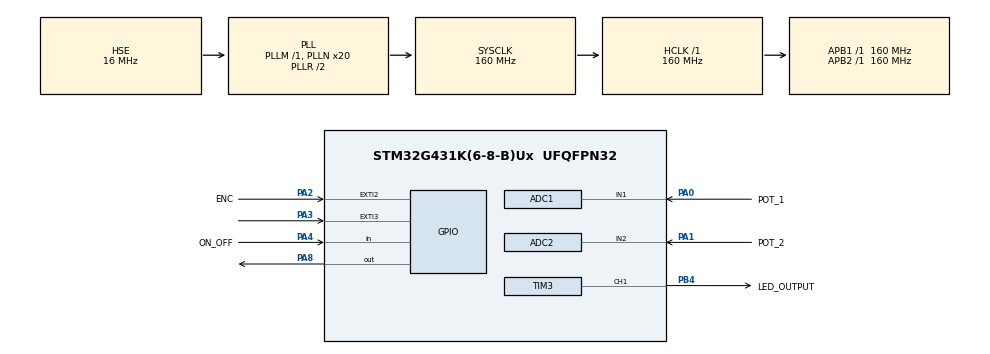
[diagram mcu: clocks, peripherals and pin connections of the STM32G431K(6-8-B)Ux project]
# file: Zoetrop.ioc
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ADC1.Channel-0\#ChannelRegularConversion=ADC_CHANNEL_1
ADC1.ContinuousConvMode=ENABLE
ADC1.NbrOfConversionFlag=1
ADC1.OffsetNumber-0\#ChannelRegularConversion=ADC_OFFSET_NONE
ADC1.Rank-0\#ChannelRegularConversion=1
ADC1.SamplingTime-0\#ChannelRegularConversion=ADC_SAMPLETIME_640CYCLES_5
ADC1.master=1
ADC2.Channel-0\#ChannelRegularConversion=ADC_CHANNEL_2
ADC2.ContinuousConvMode=ENABLE
ADC2.NbrOfConversionFlag=1
ADC2.OffsetNumber-0\#ChannelRegularConversion=ADC_OFFSET_NONE
ADC2.Rank-0\#ChannelRegularConversion=1
ADC2.SamplingTime-0\#ChannelRegularConversion=ADC_SAMPLETIME_640CYCLES_5
Mcu.Family=STM32G4
Mcu.Name=STM32G431K(6-8-B)Ux
Mcu.Package=UFQFPN32
NVIC.EXTI2_IRQn=true\:0\:0\:false\:false\:true\:true\:false
NVIC.EXTI3_IRQn=true\:0\:0\:false\:false\:true\:true\:false
NVIC.PriorityGroup=NVIC_PRIORITYGROUP_4
PA0.GPIO_Label=POT_1
PA0.Mode=IN1-Single-Ended
PA0.Signal=ADC1_IN1
PA1.GPIO_Label=POT_2
PA1.Mode=IN2-Single-Ended
PA1.Signal=ADC2_IN2
PA13.Mode=Trace_Asynchronous_SW
PA13.Signal=SYS_JTMS-SWDIO
PA14.Mode=Trace_Asynchronous_SW
PA14.Signal=SYS_JTCK-SWCLK
PA2.GPIO_Label=ENC
PA2.GPIO_ModeDefaultEXTI=GPIO_MODE_IT_RISING_FALLING
PA2.Signal=GPXTI2
PA3.Signal=GPXTI3
PA4.GPIO_Label=ON_OFF
PA4.Signal=GPIO_Input
PA8.PinState=GPIO_PIN_SET
PA8.Signal=GPIO_Output
PB3.Mode=Trace_Asynchronous_SW
PB3.Signal=SYS_JTDO-SWO
PB4.GPIO_Label=LED_OUTPUT
PB4.Signal=S_TIM3_CH1
PF0-OSC_IN.Mode=HSE-External-Oscillator
PF0-OSC_IN.Signal=RCC_OSC_IN
PF1-OSC_OUT.Mode=HSE-External-Oscillator
PF1-OSC_OUT.Signal=RCC_OSC_OUT
ProjectManager.HeapSize=0x200
ProjectManager.StackSize=0x400
ProjectManager.TargetToolchain=STM32CubeIDE
RCC.ADC12Freq_Value=160000000
RCC.AHBFreq_Value=160000000
RCC.APB1Freq_Value=160000000
RCC.APB1TimFreq_Value=160000000
RCC.APB2Freq_Value=160000000
RCC.APB2TimFreq_Value=160000000
RCC.CortexFreq_Value=160000000
RCC.EXTERNAL_CLOCK_VALUE=12288000
RCC.HCLKFreq_Value=160000000
RCC.HSE_VALUE=16000000
RCC.HSI48_VALUE=48000000
RCC.HSI_VALUE=16000000
RCC.LSE_VALUE=32768
RCC.PLLN=20
RCC.PLLSourceVirtual=RCC_PLLSOURCE_HSE
RCC.SYSCLKFreq_VALUE=160000000
RCC.SYSCLKSource=RCC_SYSCLKSOURCE_PLLCLK
RCC.USBFreq_Value=160000000
RCC.VCOOutputFreq_Value=320000000
SH.S_TIM3_CH1.0=TIM3_CH1,PWM Generation1 CH1
TIM1.PeriodNoDither=8000
TIM2.PeriodNoDither=100000000
TIM2.Prescaler=1599
TIM3.Channel-PWM\ Generation1\ CH1=TIM_CHANNEL_1
TIM3.ClockDivision=TIM_CLOCKDIVISION_DIV4
TIM3.OCMode_PWM-PWM\ Generation1\ CH1=TIM_OCMODE_PWM1
TIM3.Prescaler=1599
VP_SYS_VS_DBSignals.Mode=DisableDeadBatterySignals
VP_TIM1_VS_ClockSourceINT.Mode=Internal
VP_TIM2_VS_ClockSourceINT.Mode=Internal
VP_TIM3_VS_ClockSourceINT.Mode=Internal
board=custom

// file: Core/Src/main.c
/* USER CODE BEGIN Header */
/**
  ******************************************************************************
  * @file           : main.c
  * @brief          : Main program body
  ******************************************************************************
  * @attention
  *
  * <h2><center>&copy; Copyright (c) 2021 STMicroelectronics.
  * All rights reserved.</center></h2>
  *
  * This software component is licensed by ST under BSD 3-Clause license,
  * the "License"; You may not use this file except in compliance with the
  * License. You may obtain a copy of the License at:
  *                        opensource.org/licenses/BSD-3-Clause
  *
  ******************************************************************************
  */
/* USER CODE END Header */
#include "main.h"

/* USER CODE BEGIN Includes */

#include <commons.h>
#include <timers.h>
#include <adc.h>
#include <gpio.h>
#include <encoder.h>

/* USER CODE END Includes */

TIM_HandleTypeDef htim3;

void SystemClock_Config(void);
static void MX_GPIO_Init(void);
static void MX_ADC1_Init(void);
static void MX_ADC2_Init(void);
static void MX_TIM1_Init(void);
static void MX_TIM2_Init(void);
static void MX_TIM3_Init(void);

int main(void)
{

  /* MCU Configuration--------------------------------------------------------*/

  /* Reset of all peripherals, Initializes the Flash interface and the Systick. */
  HAL_Init();

  /* Configure the system clock */
  SystemClock_Config();

  /* Initialize all configured peripherals */
  MX_GPIO_Init();
  MX_ADC1_Init();
  MX_ADC2_Init();
  MX_TIM1_Init();
  MX_TIM2_Init();
  MX_TIM3_Init();
  /* USER CODE BEGIN 2 */

  //Initialize timers
  adc_init();
  timers_init();
  timers_enablePWM(1);

  /* USER CODE END 2 */

  /* Infinite loop */
  /* USER CODE BEGIN WHILE */
  float last_error, error, integral;
  while (1)
  {
	  //Obsługa silnika
//		 float kp = 0.1f;
//		 float ki = 0.01f;
//		 float kd = 0.002f;
//		 float derivative = 0.0f;
//		 float fPWM = 0.0f;
//		  //maksymalna prędkość silnika rad/s
//		 float max_speed = 31.4;
//		 float max_integral = 0.1f;
//		 float current_speed = encoder_getVelocity() / max_speed;   //0-1
//		 error = adc_pot_return(potenciometer_1) - current_speed;
//		 integral = integral + error;
//
//		//anti wind up
//		 integral = normalisef(integral,  0.0f, max_integral);
//
//		 derivative = error - last_error;
//		 fPWM = (kp*error) + (ki * integral) + (kd * derivative);
	  	  timers_enablePWM(1);
		 timers_setPWM(0.5f/*adc_pot_return(potenciometer_1)*/);
//		 last_error = error;

		//Obsługa LED

//		 timers_setLEDFrequency(12 * 0.1592/*stała rad/s -> Hz*/ * encoder_getVelocity());

	//	 timers_setPulseWidthLED(12 * 0.1592/*stała rad/s -> Hz*/ * encoder_getVelocity()*0.001f);

    /* USER CODE END WHILE */

  }
}

void SystemClock_Config(void)
{
  RCC_OscInitTypeDef RCC_OscInitStruct = {0};
  RCC_ClkInitTypeDef RCC_ClkInitStruct = {0};

  /** Configure the main internal regulator output voltage
  */
  HAL_PWREx_ControlVoltageScaling(PWR_REGULATOR_VOLTAGE_SCALE1_BOOST);
  /** Initializes the RCC Oscillators according to the specified parameters
  * in the RCC_OscInitTypeDef structure.
  */
  RCC_OscInitStruct.OscillatorType = RCC_OSCILLATORTYPE_HSE;
  RCC_OscInitStruct.HSEState = RCC_HSE_ON;
  RCC_OscInitStruct.PLL.PLLState = RCC_PLL_ON;
  RCC_OscInitStruct.PLL.PLLSource = RCC_PLLSOURCE_HSE;
  RCC_OscInitStruct.PLL.PLLM = RCC_PLLM_DIV1;
  RCC_OscInitStruct.PLL.PLLN = 20;
  RCC_OscInitStruct.PLL.PLLP = RCC_PLLP_DIV2;
  RCC_OscInitStruct.PLL.PLLQ = RCC_PLLQ_DIV2;
  RCC_OscInitStruct.PLL.PLLR = RCC_PLLR_DIV2;
  if (HAL_RCC_OscConfig(&RCC_OscInitStruct) != HAL_OK)
  {
    Error_Handler();
  }
  /** Initializes the CPU, AHB and APB buses clocks
  */
  RCC_ClkInitStruct.ClockType = RCC_CLOCKTYPE_HCLK|RCC_CLOCKTYPE_SYSCLK
                              |RCC_CLOCKTYPE_PCLK1|RCC_CLOCKTYPE_PCLK2;
  RCC_ClkInitStruct.SYSCLKSource = RCC_SYSCLKSOURCE_PLLCLK;
  RCC_ClkInitStruct.AHBCLKDivider = RCC_SYSCLK_DIV1;
  RCC_ClkInitStruct.APB1CLKDivider = RCC_HCLK_DIV1;
  RCC_ClkInitStruct.APB2CLKDivider = RCC_HCLK_DIV1;

  if (HAL_RCC_ClockConfig(&RCC_ClkInitStruct, FLASH_LATENCY_4) != HAL_OK)
  {
    Error_Handler();
  }
}

static void MX_ADC1_Init(void)
{

  LL_ADC_InitTypeDef ADC_InitStruct = {0};
  LL_ADC_REG_InitTypeDef ADC_REG_InitStruct = {0};
  LL_ADC_CommonInitTypeDef ADC_CommonInitStruct = {0};

  LL_GPIO_InitTypeDef GPIO_InitStruct = {0};
  RCC_PeriphCLKInitTypeDef PeriphClkInit = {0};

  /** Initializes the peripherals clocks
  */
  PeriphClkInit.PeriphClockSelection = RCC_PERIPHCLK_ADC12;
  PeriphClkInit.Adc12ClockSelection = RCC_ADC12CLKSOURCE_SYSCLK;
  if (HAL_RCCEx_PeriphCLKConfig(&PeriphClkInit) != HAL_OK)
  {
    Error_Handler();
  }

  /* Peripheral clock enable */
  LL_AHB2_GRP1_EnableClock(LL_AHB2_GRP1_PERIPH_ADC12);

  LL_AHB2_GRP1_EnableClock(LL_AHB2_GRP1_PERIPH_GPIOA);
  /**ADC1 GPIO Configuration
  PA0   ------> ADC1_IN1
  */
  GPIO_InitStruct.Pin = POT_1_Pin;
  GPIO_InitStruct.Mode = LL_GPIO_MODE_ANALOG;
  GPIO_InitStruct.Pull = LL_GPIO_PULL_NO;
  LL_GPIO_Init(POT_1_GPIO_Port, &GPIO_InitStruct);

  /** Common config
  */
  ADC_InitStruct.Resolution = LL_ADC_RESOLUTION_12B;
  ADC_InitStruct.DataAlignment = LL_ADC_DATA_ALIGN_RIGHT;
  ADC_InitStruct.LowPowerMode = LL_ADC_LP_MODE_NONE;
  LL_ADC_Init(ADC1, &ADC_InitStruct);
  ADC_REG_InitStruct.TriggerSource = LL_ADC_REG_TRIG_SOFTWARE;
  ADC_REG_InitStruct.SequencerLength = LL_ADC_REG_SEQ_SCAN_DISABLE;
  ADC_REG_InitStruct.SequencerDiscont = LL_ADC_REG_SEQ_DISCONT_DISABLE;
  ADC_REG_InitStruct.ContinuousMode = LL_ADC_REG_CONV_CONTINUOUS;
  ADC_REG_InitStruct.DMATransfer = LL_ADC_REG_DMA_TRANSFER_NONE;
  ADC_REG_InitStruct.Overrun = LL_ADC_REG_OVR_DATA_PRESERVED;
  LL_ADC_REG_Init(ADC1, &ADC_REG_InitStruct);
  LL_ADC_SetGainCompensation(ADC1, 0);
  LL_ADC_SetOverSamplingScope(ADC1, LL_ADC_OVS_DISABLE);
  ADC_CommonInitStruct.CommonClock = LL_ADC_CLOCK_SYNC_PCLK_DIV4;
  ADC_CommonInitStruct.Multimode = LL_ADC_MULTI_INDEPENDENT;
  LL_ADC_CommonInit(__LL_ADC_COMMON_INSTANCE(ADC1), &ADC_CommonInitStruct);

  /* Disable ADC deep power down (enabled by default after reset state) */
  LL_ADC_DisableDeepPowerDown(ADC1);
  /* Enable ADC internal voltage regulator */
  LL_ADC_EnableInternalRegulator(ADC1);
  /* Delay for ADC internal voltage regulator stabilization. */
  /* Compute number of CPU cycles to wait for, from delay in us. */
  /* Note: Variable divided by 2 to compensate partially */
  /* CPU processing cycles (depends on compilation optimization). */
  /* Note: If system core clock frequency is below 200kHz, wait time */
  /* is only a few CPU processing cycles. */
  uint32_t wait_loop_index;
  wait_loop_index = ((LL_ADC_DELAY_INTERNAL_REGUL_STAB_US * (SystemCoreClock / (100000 * 2))) / 10);
  while(wait_loop_index != 0)
  {
    wait_loop_index--;
  }
  /** Configure Regular Channel
  */
  LL_ADC_REG_SetSequencerRanks(ADC1, LL_ADC_REG_RANK_1, LL_ADC_CHANNEL_1);
  LL_ADC_SetChannelSamplingTime(ADC1, LL_ADC_CHANNEL_1, LL_ADC_SAMPLINGTIME_640CYCLES_5);
  LL_ADC_SetChannelSingleDiff(ADC1, LL_ADC_CHANNEL_1, LL_ADC_SINGLE_ENDED);

}

static void MX_ADC2_Init(void)
{

  LL_ADC_InitTypeDef ADC_InitStruct = {0};
  LL_ADC_REG_InitTypeDef ADC_REG_InitStruct = {0};

  LL_GPIO_InitTypeDef GPIO_InitStruct = {0};
  RCC_PeriphCLKInitTypeDef PeriphClkInit = {0};

  /** Initializes the peripherals clocks
  */
  PeriphClkInit.PeriphClockSelection = RCC_PERIPHCLK_ADC12;
  PeriphClkInit.Adc12ClockSelection = RCC_ADC12CLKSOURCE_SYSCLK;
  if (HAL_RCCEx_PeriphCLKConfig(&PeriphClkInit) != HAL_OK)
  {
    Error_Handler();
  }

  /* Peripheral clock enable */
  LL_AHB2_GRP1_EnableClock(LL_AHB2_GRP1_PERIPH_ADC12);

  LL_AHB2_GRP1_EnableClock(LL_AHB2_GRP1_PERIPH_GPIOA);
  /**ADC2 GPIO Configuration
  PA1   ------> ADC2_IN2
  */
  GPIO_InitStruct.Pin = POT_2_Pin;
  GPIO_InitStruct.Mode = LL_GPIO_MODE_ANALOG;
  GPIO_InitStruct.Pull = LL_GPIO_PULL_NO;
  LL_GPIO_Init(POT_2_GPIO_Port, &GPIO_InitStruct);

  /** Common config
  */
  ADC_InitStruct.Resolution = LL_ADC_RESOLUTION_12B;
  ADC_InitStruct.DataAlignment = LL_ADC_DATA_ALIGN_RIGHT;
  ADC_InitStruct.LowPowerMode = LL_ADC_LP_MODE_NONE;
  LL_ADC_Init(ADC2, &ADC_InitStruct);
  ADC_REG_InitStruct.TriggerSource = LL_ADC_REG_TRIG_SOFTWARE;
  ADC_REG_InitStruct.SequencerLength = LL_ADC_REG_SEQ_SCAN_DISABLE;
  ADC_REG_InitStruct.SequencerDiscont = LL_ADC_REG_SEQ_DISCONT_DISABLE;
  ADC_REG_InitStruct.ContinuousMode = LL_ADC_REG_CONV_CONTINUOUS;
  ADC_REG_InitStruct.DMATransfer = LL_ADC_REG_DMA_TRANSFER_NONE;
  ADC_REG_InitStruct.Overrun = LL_ADC_REG_OVR_DATA_PRESERVED;
  LL_ADC_REG_Init(ADC2, &ADC_REG_InitStruct);
  LL_ADC_SetGainCompensation(ADC2, 0);
  LL_ADC_SetOverSamplingScope(ADC2, LL_ADC_OVS_DISABLE);

  /* Disable ADC deep power down (enabled by default after reset state) */
  LL_ADC_DisableDeepPowerDown(ADC2);
  /* Enable ADC internal voltage regulator */
  LL_ADC_EnableInternalRegulator(ADC2);
  /* Delay for ADC internal voltage regulator stabilization. */
  /* Compute number of CPU cycles to wait for, from delay in us. */
  /* Note: Variable divided by 2 to compensate partially */
  /* CPU processing cycles (depends on compilation optimization). */
  /* Note: If system core clock frequency is below 200kHz, wait time */
  /* is only a few CPU processing cycles. */
  uint32_t wait_loop_index;
  wait_loop_index = ((LL_ADC_DELAY_INTERNAL_REGUL_STAB_US * (SystemCoreClock / (100000 * 2))) / 10);
  while(wait_loop_index != 0)
  {
    wait_loop_index--;
  }
  /** Configure Regular Channel
  */
  LL_ADC_REG_SetSequencerRanks(ADC2, LL_ADC_REG_RANK_1, LL_ADC_CHANNEL_2);
  LL_ADC_SetChannelSamplingTime(ADC2, LL_ADC_CHANNEL_2, LL_ADC_SAMPLINGTIME_640CYCLES_5);
  LL_ADC_SetChannelSingleDiff(ADC2, LL_ADC_CHANNEL_2, LL_ADC_SINGLE_ENDED);

}

static void MX_TIM1_Init(void)
{

  LL_TIM_InitTypeDef TIM_InitStruct = {0};

  /* Peripheral clock enable */
  LL_APB2_GRP1_EnableClock(LL_APB2_GRP1_PERIPH_TIM1);

  TIM_InitStruct.Prescaler = 0;
  TIM_InitStruct.CounterMode = LL_TIM_COUNTERMODE_UP;
  TIM_InitStruct.Autoreload = 8000;
  TIM_InitStruct.ClockDivision = LL_TIM_CLOCKDIVISION_DIV1;
  TIM_InitStruct.RepetitionCounter = 0;
  LL_TIM_Init(TIM1, &TIM_InitStruct);
  LL_TIM_DisableARRPreload(TIM1);
  LL_TIM_SetClockSource(TIM1, LL_TIM_CLOCKSOURCE_INTERNAL);
  LL_TIM_SetTriggerOutput(TIM1, LL_TIM_TRGO_RESET);
  LL_TIM_SetTriggerOutput2(TIM1, LL_TIM_TRGO2_RESET);
  LL_TIM_DisableMasterSlaveMode(TIM1);

}

static void MX_TIM2_Init(void)
{

  LL_TIM_InitTypeDef TIM_InitStruct = {0};

  /* Peripheral clock enable */
  LL_APB1_GRP1_EnableClock(LL_APB1_GRP1_PERIPH_TIM2);

  TIM_InitStruct.Prescaler = 1599;
  TIM_InitStruct.CounterMode = LL_TIM_COUNTERMODE_UP;
  TIM_InitStruct.Autoreload = 1.0E8;
  TIM_InitStruct.ClockDivision = LL_TIM_CLOCKDIVISION_DIV1;
  LL_TIM_Init(TIM2, &TIM_InitStruct);
  LL_TIM_DisableARRPreload(TIM2);
  LL_TIM_SetClockSource(TIM2, LL_TIM_CLOCKSOURCE_INTERNAL);
  LL_TIM_SetTriggerOutput(TIM2, LL_TIM_TRGO_RESET);
  LL_TIM_DisableMasterSlaveMode(TIM2);

}

static void MX_TIM3_Init(void)
{

  TIM_ClockConfigTypeDef sClockSourceConfig = {0};
  TIM_MasterConfigTypeDef sMasterConfig = {0};
  TIM_OC_InitTypeDef sConfigOC = {0};

  htim3.Instance = TIM3;
  htim3.Init.Prescaler = 1599;
  htim3.Init.CounterMode = TIM_COUNTERMODE_UP;
  htim3.Init.Period = 65535;
  htim3.Init.ClockDivision = TIM_CLOCKDIVISION_DIV4;
  htim3.Init.AutoReloadPreload = TIM_AUTORELOAD_PRELOAD_DISABLE;
  if (HAL_TIM_Base_Init(&htim3) != HAL_OK)
  {
    Error_Handler();
  }
  sClockSourceConfig.ClockSource = TIM_CLOCKSOURCE_INTERNAL;
  if (HAL_TIM_ConfigClockSource(&htim3, &sClockSourceConfig) != HAL_OK)
  {
    Error_Handler();
  }
  if (HAL_TIM_PWM_Init(&htim3) != HAL_OK)
  {
    Error_Handler();
  }
  sMasterConfig.MasterOutputTrigger = TIM_TRGO_RESET;
  sMasterConfig.MasterSlaveMode = TIM_MASTERSLAVEMODE_DISABLE;
  if (HAL_TIMEx_MasterConfigSynchronization(&htim3, &sMasterConfig) != HAL_OK)
  {
    Error_Handler();
  }
  sConfigOC.OCMode = TIM_OCMODE_PWM1;
  sConfigOC.Pulse = 0;
  sConfigOC.OCPolarity = TIM_OCPOLARITY_HIGH;
  sConfigOC.OCFastMode = TIM_OCFAST_DISABLE;
  if (HAL_TIM_PWM_ConfigChannel(&htim3, &sConfigOC, TIM_CHANNEL_1) != HAL_OK)
  {
    Error_Handler();
  }
  HAL_TIM_MspPostInit(&htim3);

}

static void MX_GPIO_Init(void)
{
  LL_EXTI_InitTypeDef EXTI_InitStruct = {0};
  LL_GPIO_InitTypeDef GPIO_InitStruct = {0};

  /* GPIO Ports Clock Enable */
  LL_AHB2_GRP1_EnableClock(LL_AHB2_GRP1_PERIPH_GPIOF);
  LL_AHB2_GRP1_EnableClock(LL_AHB2_GRP1_PERIPH_GPIOA);
  LL_AHB2_GRP1_EnableClock(LL_AHB2_GRP1_PERIPH_GPIOB);

  /**/
  LL_GPIO_SetOutputPin(GPIOA, LL_GPIO_PIN_8);

  /**/
  LL_SYSCFG_SetEXTISource(LL_SYSCFG_EXTI_PORTA, LL_SYSCFG_EXTI_LINE2);

  /**/
  LL_SYSCFG_SetEXTISource(LL_SYSCFG_EXTI_PORTA, LL_SYSCFG_EXTI_LINE3);

  /**/
  EXTI_InitStruct.Line_0_31 = LL_EXTI_LINE_2;
  EXTI_InitStruct.LineCommand = ENABLE;
  EXTI_InitStruct.Mode = LL_EXTI_MODE_IT;
  EXTI_InitStruct.Trigger = LL_EXTI_TRIGGER_RISING_FALLING;
  LL_EXTI_Init(&EXTI_InitStruct);

  /**/
  EXTI_InitStruct.Line_0_31 = LL_EXTI_LINE_3;
  EXTI_InitStruct.LineCommand = ENABLE;
  EXTI_InitStruct.Mode = LL_EXTI_MODE_IT;
  EXTI_InitStruct.Trigger = LL_EXTI_TRIGGER_RISING;
  LL_EXTI_Init(&EXTI_InitStruct);

  /**/
  LL_GPIO_SetPinPull(ENC_GPIO_Port, ENC_Pin, LL_GPIO_PULL_NO);

  /**/
  LL_GPIO_SetPinPull(GPIOA, LL_GPIO_PIN_3, LL_GPIO_PULL_NO);

  /**/
  LL_GPIO_SetPinMode(ENC_GPIO_Port, ENC_Pin, LL_GPIO_MODE_INPUT);

  /**/
  LL_GPIO_SetPinMode(GPIOA, LL_GPIO_PIN_3, LL_GPIO_MODE_INPUT);

  /**/
  GPIO_InitStruct.Pin = ON_OFF_Pin;
  GPIO_InitStruct.Mode = LL_GPIO_MODE_INPUT;
  GPIO_InitStruct.Pull = LL_GPIO_PULL_NO;
  LL_GPIO_Init(ON_OFF_GPIO_Port, &GPIO_InitStruct);

  /**/
  GPIO_InitStruct.Pin = LL_GPIO_PIN_8;
  GPIO_InitStruct.Mode = LL_GPIO_MODE_OUTPUT;
  GPIO_InitStruct.Speed = LL_GPIO_SPEED_FREQ_LOW;
  GPIO_InitStruct.OutputType = LL_GPIO_OUTPUT_PUSHPULL;
  GPIO_InitStruct.Pull = LL_GPIO_PULL_NO;
  LL_GPIO_Init(GPIOA, &GPIO_InitStruct);

  /* EXTI interrupt init*/
  NVIC_SetPriority(EXTI2_IRQn, NVIC_EncodePriority(NVIC_GetPriorityGrouping(),0, 0));
  NVIC_EnableIRQ(EXTI2_IRQn);
  NVIC_SetPriority(EXTI3_IRQn, NVIC_EncodePriority(NVIC_GetPriorityGrouping(),0, 0));
  NVIC_EnableIRQ(EXTI3_IRQn);

}

void Error_Handler(void)
{
  __disable_irq();
  while (1)
  {
  }
}
